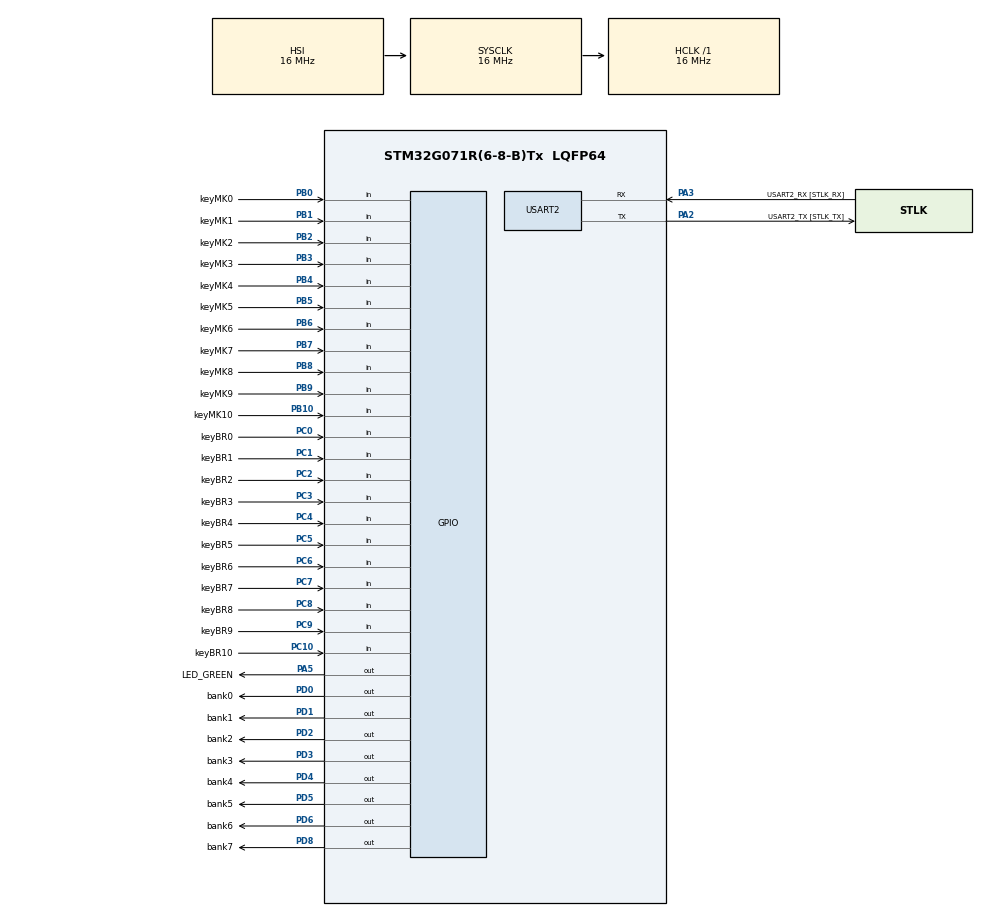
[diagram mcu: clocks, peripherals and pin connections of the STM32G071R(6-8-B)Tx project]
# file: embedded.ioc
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Mcu.Family=STM32G0
Mcu.Name=STM32G071R(6-8-B)Tx
Mcu.Package=LQFP64
PA13.GPIO_Label=TMS
PA13.Mode=Serial_Wire
PA13.Signal=SYS_SWDIO
PA14-BOOT0.GPIO_Label=TCK
PA14-BOOT0.Mode=Serial_Wire
PA14-BOOT0.Signal=SYS_SWCLK
PA2.GPIO_Label=USART2_TX [STLK_TX]
PA2.GPIO_PuPd=GPIO_PULLUP
PA2.Mode=Asynchronous
PA2.Signal=USART2_TX
PA3.GPIO_Label=USART2_RX [STLK_RX]
PA3.GPIO_PuPd=GPIO_PULLUP
PA3.Mode=Asynchronous
PA3.Signal=USART2_RX
PA5.GPIO_Label=LED_GREEN
PA5.GPIO_Speed=GPIO_SPEED_FREQ_HIGH
PA5.Signal=GPIO_Output
PB0.GPIO_Label=keyMK0
PB0.Signal=GPIO_Input
PB1.GPIO_Label=keyMK1
PB1.Signal=GPIO_Input
PB10.GPIO_Label=keyMK10
PB10.Signal=GPIO_Input
PB2.GPIO_Label=keyMK2
PB2.Signal=GPIO_Input
PB3.GPIO_Label=keyMK3
PB3.Signal=GPIO_Input
PB4.GPIO_Label=keyMK4
PB4.Signal=GPIO_Input
PB5.GPIO_Label=keyMK5
PB5.Signal=GPIO_Input
PB6.GPIO_Label=keyMK6
PB6.Signal=GPIO_Input
PB7.GPIO_Label=keyMK7
PB7.Signal=GPIO_Input
PB8.GPIO_Label=keyMK8
PB8.Signal=GPIO_Input
PB9.GPIO_Label=keyMK9
PB9.Signal=GPIO_Input
PC0.GPIO_Label=keyBR0
PC0.Signal=GPIO_Input
PC1.GPIO_Label=keyBR1
PC1.Signal=GPIO_Input
PC10.GPIO_Label=keyBR10
PC10.Signal=GPIO_Input
PC13.Mode=SYS_WakeUp1
PC13.Signal=SYS_WKUP2
PC14-OSC32_IN\ (PC14).Mode=LSE-External-Oscillator
PC14-OSC32_IN\ (PC14).Signal=RCC_OSC32_IN
PC15-OSC32_OUT\ (PC15).Mode=LSE-External-Oscillator
PC15-OSC32_OUT\ (PC15).Signal=RCC_OSC32_OUT
PC2.GPIO_Label=keyBR2
PC2.Signal=GPIO_Input
PC3.GPIO_Label=keyBR3
PC3.Signal=GPIO_Input
PC4.GPIO_Label=keyBR4
PC4.Signal=GPIO_Input
PC5.GPIO_Label=keyBR5
PC5.Signal=GPIO_Input
PC6.GPIO_Label=keyBR6
PC6.Signal=GPIO_Input
PC7.GPIO_Label=keyBR7
PC7.Signal=GPIO_Input
PC8.GPIO_Label=keyBR8
PC8.Signal=GPIO_Input
PC9.GPIO_Label=keyBR9
PC9.Signal=GPIO_Input
PD0.GPIO_Label=bank0
PD0.Signal=GPIO_Output
PD1.GPIO_Label=bank1
PD1.Signal=GPIO_Output
PD2.GPIO_Label=bank2
PD2.Signal=GPIO_Output
PD3.GPIO_Label=bank3
PD3.Signal=GPIO_Output
PD4.GPIO_Label=bank4
PD4.Signal=GPIO_Output
PD5.GPIO_Label=bank5
PD5.Signal=GPIO_Output
PD6.GPIO_Label=bank6
PD6.Signal=GPIO_Output
PD8.GPIO_Label=bank7
PD8.Signal=GPIO_Output
PF0-OSC_IN\ (PF0).GPIO_Label=MCO
PF0-OSC_IN\ (PF0).Mode=HSE-External-Clock-Source
PF0-OSC_IN\ (PF0).Signal=RCC_OSC_IN
ProjectManager.HeapSize=0x200
ProjectManager.StackSize=0x400
ProjectManager.TargetToolchain=STM32CubeIDE
RCC.AHBFreq_Value=16000000
RCC.CortexFreq_Value=16000000
RCC.EXTERNAL_CLOCK_VALUE=12288000
RCC.HCLKFreq_Value=16000000
RCC.HSE_VALUE=8000000
RCC.HSI_VALUE=16000000
RCC.SYSCLKFreq_VALUE=16000000
RCC.VCOOutputFreq_Value=128000000
TIM2.Prescaler=80
USART2.VirtualMode-Asynchronous=VM_ASYNC
VP_LPTIM1_VS_LPTIM_counterModeInternalClock.Mode=Counts__internal_clock_event_00
VP_RTC_VS_RTC_Activate.Mode=RTC_Enabled
VP_SYS_VS_DBSignals.Mode=DisableDeadBatterySignals
VP_TIM2_VS_ClockSourceINT.Mode=Internal
board=NUCLEO-G071RB

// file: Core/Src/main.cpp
/* USER CODE BEGIN Header */
/**
  ******************************************************************************
  * @file           : main.c
  * @brief          : Main program body
  ******************************************************************************
  * @attention
  *
  * Copyright (c) 2022 STMicroelectronics.
  * All rights reserved.
  *
  * This software is licensed under terms that can be found in the LICENSE file
  * in the root directory of this software component.
  * If no LICENSE file comes with this software, it is provided AS-IS.
  *
  ******************************************************************************
  */
/* USER CODE END Header */
#include "main.h"

/* USER CODE BEGIN Includes */
#include "Keyboard.h"
#include "MIDI.h"
/* USER CODE END Includes */

 LPTIM_HandleTypeDef hlptim1;

RTC_HandleTypeDef hrtc;

TIM_HandleTypeDef htim2;

UART_HandleTypeDef huart2;

void SystemClock_Config(void);
static void MX_GPIO_Init(void);
static void MX_USART2_UART_Init(void);
static void MX_LPTIM1_Init(void);
static void MX_RTC_Init(void);
static void MX_TIM2_Init(void);

/* USER CODE BEGIN 0 */
Keyboard keyboard0;
MIDI midi;
/* USER CODE END 0 */

int main(void)
{

  /* MCU Configuration--------------------------------------------------------*/

  /* Reset of all peripherals, Initializes the Flash interface and the Systick. */
  HAL_Init();

  /* Configure the system clock */
  SystemClock_Config();

  /* Initialize all configured peripherals */
  MX_GPIO_Init();
  MX_USART2_UART_Init();
  MX_LPTIM1_Init();
  MX_RTC_Init();
  MX_TIM2_Init();

  /* Infinite loop */
  while (1)
  {
	for (int keysCount = 0; int keysCount < KEY_COUNT_BANK; ++int keysCount) {
		for (int bankCount = 0; int bankCount < BANK_COUNT; ++int bankCount) {

		}
	}
  }
}

void SystemClock_Config(void)
{
  RCC_OscInitTypeDef RCC_OscInitStruct = {0};
  RCC_ClkInitTypeDef RCC_ClkInitStruct = {0};

  /** Configure the main internal regulator output voltage
  */
  HAL_PWREx_ControlVoltageScaling(PWR_REGULATOR_VOLTAGE_SCALE1);

  /** Initializes the RCC Oscillators according to the specified parameters
  * in the RCC_OscInitTypeDef structure.
  */
  RCC_OscInitStruct.OscillatorType = RCC_OSCILLATORTYPE_HSI|RCC_OSCILLATORTYPE_LSI;
  RCC_OscInitStruct.HSIState = RCC_HSI_ON;
  RCC_OscInitStruct.HSIDiv = RCC_HSI_DIV1;
  RCC_OscInitStruct.HSICalibrationValue = RCC_HSICALIBRATION_DEFAULT;
  RCC_OscInitStruct.LSIState = RCC_LSI_ON;
  RCC_OscInitStruct.PLL.PLLState = RCC_PLL_NONE;
  if (HAL_RCC_OscConfig(&RCC_OscInitStruct) != HAL_OK)
  {
    Error_Handler();
  }

  /** Initializes the CPU, AHB and APB buses clocks
  */
  RCC_ClkInitStruct.ClockType = RCC_CLOCKTYPE_HCLK|RCC_CLOCKTYPE_SYSCLK
                              |RCC_CLOCKTYPE_PCLK1;
  RCC_ClkInitStruct.SYSCLKSource = RCC_SYSCLKSOURCE_HSI;
  RCC_ClkInitStruct.AHBCLKDivider = RCC_SYSCLK_DIV1;
  RCC_ClkInitStruct.APB1CLKDivider = RCC_HCLK_DIV1;

  if (HAL_RCC_ClockConfig(&RCC_ClkInitStruct, FLASH_LATENCY_0) != HAL_OK)
  {
    Error_Handler();
  }
}

static void MX_LPTIM1_Init(void)
{

  hlptim1.Instance = LPTIM1;
  hlptim1.Init.Clock.Source = LPTIM_CLOCKSOURCE_APBCLOCK_LPOSC;
  hlptim1.Init.Clock.Prescaler = LPTIM_PRESCALER_DIV1;
  hlptim1.Init.Trigger.Source = LPTIM_TRIGSOURCE_SOFTWARE;
  hlptim1.Init.OutputPolarity = LPTIM_OUTPUTPOLARITY_HIGH;
  hlptim1.Init.UpdateMode = LPTIM_UPDATE_IMMEDIATE;
  hlptim1.Init.CounterSource = LPTIM_COUNTERSOURCE_INTERNAL;
  hlptim1.Init.Input1Source = LPTIM_INPUT1SOURCE_GPIO;
  hlptim1.Init.Input2Source = LPTIM_INPUT2SOURCE_GPIO;
  if (HAL_LPTIM_Init(&hlptim1) != HAL_OK)
  {
    Error_Handler();
  }

}

static void MX_RTC_Init(void)
{

  /** Initialize RTC Only
  */
  hrtc.Instance = RTC;
  hrtc.Init.HourFormat = RTC_HOURFORMAT_24;
  hrtc.Init.AsynchPrediv = 127;
  hrtc.Init.SynchPrediv = 255;
  hrtc.Init.OutPut = RTC_OUTPUT_DISABLE;
  hrtc.Init.OutPutRemap = RTC_OUTPUT_REMAP_NONE;
  hrtc.Init.OutPutPolarity = RTC_OUTPUT_POLARITY_HIGH;
  hrtc.Init.OutPutType = RTC_OUTPUT_TYPE_OPENDRAIN;
  hrtc.Init.OutPutPullUp = RTC_OUTPUT_PULLUP_NONE;
  if (HAL_RTC_Init(&hrtc) != HAL_OK)
  {
    Error_Handler();
  }

}

static void MX_TIM2_Init(void)
{

  TIM_ClockConfigTypeDef sClockSourceConfig = {0};
  TIM_MasterConfigTypeDef sMasterConfig = {0};

  htim2.Instance = TIM2;
  htim2.Init.Prescaler = 80;
  htim2.Init.CounterMode = TIM_COUNTERMODE_UP;
  htim2.Init.Period = 4294967295;
  htim2.Init.ClockDivision = TIM_CLOCKDIVISION_DIV1;
  htim2.Init.AutoReloadPreload = TIM_AUTORELOAD_PRELOAD_DISABLE;
  if (HAL_TIM_Base_Init(&htim2) != HAL_OK)
  {
    Error_Handler();
  }
  sClockSourceConfig.ClockSource = TIM_CLOCKSOURCE_INTERNAL;
  if (HAL_TIM_ConfigClockSource(&htim2, &sClockSourceConfig) != HAL_OK)
  {
    Error_Handler();
  }
  sMasterConfig.MasterOutputTrigger = TIM_TRGO_RESET;
  sMasterConfig.MasterSlaveMode = TIM_MASTERSLAVEMODE_DISABLE;
  if (HAL_TIMEx_MasterConfigSynchronization(&htim2, &sMasterConfig) != HAL_OK)
  {
    Error_Handler();
  }

}

static void MX_USART2_UART_Init(void)
{

  huart2.Instance = USART2;
  huart2.Init.BaudRate = 115200;
  huart2.Init.WordLength = UART_WORDLENGTH_8B;
  huart2.Init.StopBits = UART_STOPBITS_1;
  huart2.Init.Parity = UART_PARITY_NONE;
  huart2.Init.Mode = UART_MODE_TX_RX;
  huart2.Init.HwFlowCtl = UART_HWCONTROL_NONE;
  huart2.Init.OverSampling = UART_OVERSAMPLING_16;
  huart2.Init.OneBitSampling = UART_ONE_BIT_SAMPLE_DISABLE;
  huart2.Init.ClockPrescaler = UART_PRESCALER_DIV1;
  huart2.AdvancedInit.AdvFeatureInit = UART_ADVFEATURE_NO_INIT;
  if (HAL_UART_Init(&huart2) != HAL_OK)
  {
    Error_Handler();
  }
  if (HAL_UARTEx_SetTxFifoThreshold(&huart2, UART_TXFIFO_THRESHOLD_1_8) != HAL_OK)
  {
    Error_Handler();
  }
  if (HAL_UARTEx_SetRxFifoThreshold(&huart2, UART_RXFIFO_THRESHOLD_1_8) != HAL_OK)
  {
    Error_Handler();
  }
  if (HAL_UARTEx_DisableFifoMode(&huart2) != HAL_OK)
  {
    Error_Handler();
  }

}

static void MX_GPIO_Init(void)
{
  GPIO_InitTypeDef GPIO_InitStruct = {0};

  /* GPIO Ports Clock Enable */
  __HAL_RCC_GPIOC_CLK_ENABLE();
  __HAL_RCC_GPIOF_CLK_ENABLE();
  __HAL_RCC_GPIOA_CLK_ENABLE();
  __HAL_RCC_GPIOB_CLK_ENABLE();
  __HAL_RCC_GPIOD_CLK_ENABLE();

  /*Configure GPIO pin Output Level */
  HAL_GPIO_WritePin(LED_GREEN_GPIO_Port, LED_GREEN_Pin, GPIO_PIN_RESET);

  /*Configure GPIO pin Output Level */
  HAL_GPIO_WritePin(GPIOD, bank7_Pin|bank0_Pin|bank1_Pin|bank2_Pin
                          |bank3_Pin|bank4_Pin|bank5_Pin|bank6_Pin, GPIO_PIN_RESET);

  /*Configure GPIO pins : keyBR0_Pin keyBR1_Pin keyBR2_Pin keyBR3_Pin
                           keyBR4_Pin keyBR5_Pin keyBR6_Pin keyBR7_Pin
                           keyBR8_Pin keyBR9_Pin keyBR10_Pin */
  GPIO_InitStruct.Pin = keyBR0_Pin|keyBR1_Pin|keyBR2_Pin|keyBR3_Pin
                          |keyBR4_Pin|keyBR5_Pin|keyBR6_Pin|keyBR7_Pin
                          |keyBR8_Pin|keyBR9_Pin|keyBR10_Pin;
  GPIO_InitStruct.Mode = GPIO_MODE_INPUT;
  GPIO_InitStruct.Pull = GPIO_NOPULL;
  HAL_GPIO_Init(GPIOC, &GPIO_InitStruct);

  /*Configure GPIO pin : LED_GREEN_Pin */
  GPIO_InitStruct.Pin = LED_GREEN_Pin;
  GPIO_InitStruct.Mode = GPIO_MODE_OUTPUT_PP;
  GPIO_InitStruct.Pull = GPIO_NOPULL;
  GPIO_InitStruct.Speed = GPIO_SPEED_FREQ_HIGH;
  HAL_GPIO_Init(LED_GREEN_GPIO_Port, &GPIO_InitStruct);

  /*Configure GPIO pins : keyMK0_Pin keyMK1_Pin keyMK2_Pin keyMK10_Pin
                           keyMK3_Pin keyMK4_Pin keyMK5_Pin keyMK6_Pin
                           keyMK7_Pin keyMK8_Pin keyMK9_Pin */
  GPIO_InitStruct.Pin = keyMK0_Pin|keyMK1_Pin|keyMK2_Pin|keyMK10_Pin
                          |keyMK3_Pin|keyMK4_Pin|keyMK5_Pin|keyMK6_Pin
                          |keyMK7_Pin|keyMK8_Pin|keyMK9_Pin;
  GPIO_InitStruct.Mode = GPIO_MODE_INPUT;
  GPIO_InitStruct.Pull = GPIO_NOPULL;
  HAL_GPIO_Init(GPIOB, &GPIO_InitStruct);

  /*Configure GPIO pins : bank7_Pin bank0_Pin bank1_Pin bank2_Pin
                           bank3_Pin bank4_Pin bank5_Pin bank6_Pin */
  GPIO_InitStruct.Pin = bank7_Pin|bank0_Pin|bank1_Pin|bank2_Pin
                          |bank3_Pin|bank4_Pin|bank5_Pin|bank6_Pin;
  GPIO_InitStruct.Mode = GPIO_MODE_OUTPUT_PP;
  GPIO_InitStruct.Pull = GPIO_NOPULL;
  GPIO_InitStruct.Speed = GPIO_SPEED_FREQ_LOW;
  HAL_GPIO_Init(GPIOD, &GPIO_InitStruct);

}

void Error_Handler(void)
{
  __disable_irq();
  while (1)
  {
  }
}
